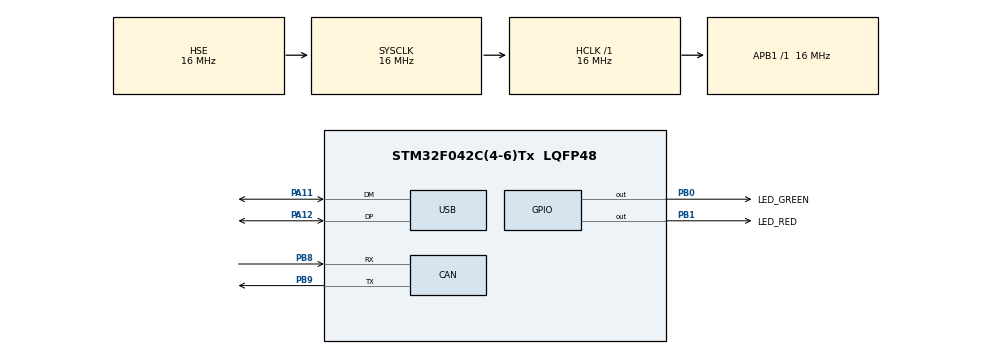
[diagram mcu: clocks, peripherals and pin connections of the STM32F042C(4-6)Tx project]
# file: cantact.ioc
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CAN.CalculateTimeBit=3000
CAN.CalculateTimeQuantum=1000.0
Mcu.Family=STM32F0
Mcu.Name=STM32F042C(4-6)Tx
Mcu.Package=LQFP48
NVIC.USB_IRQn=true\:0\:0\:false\:false\:true\:true\:true
PA11.Mode=Device
PA11.Signal=USB_DM
PA12.Mode=Device
PA12.Signal=USB_DP
PA13.Mode=Serial_Wire
PA13.Signal=SYS_SWDIO
PA14.Mode=Serial_Wire
PA14.Signal=SYS_SWCLK
PB0.GPIO_Label=LED_GREEN
PB0.Signal=GPIO_Output
PB1.GPIO_Label=LED_RED
PB1.Signal=GPIO_Output
PB8.Mode=Master
PB8.Signal=CAN_RX
PB9.Mode=Master
PB9.Signal=CAN_TX
PF0-OSC_IN.Mode=HSE-External-Oscillator
PF0-OSC_IN.Signal=RCC_OSC_IN
PF1-OSC_OUT.Mode=HSE-External-Oscillator
PF1-OSC_OUT.Signal=RCC_OSC_OUT
ProjectManager.HeapSize=0x200
ProjectManager.StackSize=0x400
ProjectManager.TargetToolchain=STM32CubeIDE
RCC.AHBFreq_Value=16000000
RCC.APB1Freq_Value=16000000
RCC.APB1TimFreq_Value=16000000
RCC.HCLKFreq_Value=16000000
RCC.HSE_VALUE=16000000
RCC.HSIState=RCC_HSI_ON
RCC.PLLMUL=RCC_PLL_MUL3
RCC.SYSCLKFreq_VALUE=16000000
RCC.SYSCLKSource=RCC_SYSCLKSOURCE_HSE
RCC.USBClockSelection=RCC_USBCLKSOURCE_PLL
RCC.USBFreq_Value=48000000
USB_DEVICE.CLASS_NAME_FS=CDC
USB_DEVICE.USBD_HandleTypeDef=hUsbDeviceFS
USB_DEVICE.VirtualMode=Cdc
USB_DEVICE.VirtualModeFS=Cdc_FS
VP_USB_DEVICE_VS_USB_DEVICE_CDC_FS.Mode=CDC_FS
board=cantact

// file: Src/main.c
/* USER CODE BEGIN Header */
/**
  ******************************************************************************
  * @file           : main.c
  * @brief          : Main program body
  ******************************************************************************
  * @attention
  *
  * <h2><center>&copy; Copyright (c) 2019 STMicroelectronics.
  * All rights reserved.</center></h2>
  *
  * This software component is licensed by ST under BSD 3-Clause license,
  * the "License"; You may not use this file except in compliance with the
  * License. You may obtain a copy of the License at:
  *                        opensource.org/licenses/BSD-3-Clause
  *
  ******************************************************************************
  */
/* USER CODE END Header */

#include "main.h"
#include "usb_device.h"

/* USER CODE BEGIN Includes */
#include "usbd_cdc_if.h"
#include "can.h"
#include "slcan.h"
#include "led.h"
/* USER CODE END Includes */

CAN_HandleTypeDef hcan;

void SystemClock_Config(void);
static void MX_GPIO_Init(void);
static void MX_CAN_Init(void);

int main(void)
{

  /* MCU Configuration--------------------------------------------------------*/

  /* Reset of all peripherals, Initializes the Flash interface and the Systick. */
  HAL_Init();

  /* Configure the system clock */
  SystemClock_Config();

  /* Initialize all configured peripherals */
  MX_GPIO_Init();
  MX_CAN_Init();
  MX_USB_DEVICE_Init();

  /* Infinite loop */
  while (1)
  {
	// turn on green LED
	HAL_GPIO_WritePin(LED_GREEN_GPIO_Port, LED_GREEN_Pin, GPIO_PIN_SET);

	// blink red LED for test
	HAL_GPIO_WritePin(LED_RED_GPIO_Port, LED_RED_Pin, GPIO_PIN_SET);
	HAL_Delay(100);
	HAL_GPIO_WritePin(LED_RED_GPIO_Port, LED_RED_Pin, GPIO_PIN_RESET);
	HAL_Delay(100);
	HAL_GPIO_WritePin(LED_RED_GPIO_Port, LED_RED_Pin, GPIO_PIN_SET);
	HAL_Delay(100);
	HAL_GPIO_WritePin(LED_RED_GPIO_Port, LED_RED_Pin, GPIO_PIN_RESET);

	// loop forever
	CAN_RxHeaderTypeDef rx_msg;
	uint8_t can_data_buf[8];
	uint32_t status;
	uint8_t msg_buf[SLCAN_MTU];

	for (;;) {
	  while (!is_can_msg_pending(CAN_RX_FIFO0))
		  led_process();
	  status = can_rx(&rx_msg, msg_buf, 3);
	  if (status == HAL_OK) {
		  status = slcan_parse_frame((uint8_t *)&msg_buf, &rx_msg, can_data_buf);
		  CDC_Transmit_FS(msg_buf, status);
	  }
	  led_process();
	}
  }
}

void SystemClock_Config(void)
{
  RCC_OscInitTypeDef RCC_OscInitStruct = {0};
  RCC_ClkInitTypeDef RCC_ClkInitStruct = {0};
  RCC_PeriphCLKInitTypeDef PeriphClkInit = {0};

  /** Initializes the CPU, AHB and APB busses clocks
  */
  RCC_OscInitStruct.OscillatorType = RCC_OSCILLATORTYPE_HSE;
  RCC_OscInitStruct.HSEState = RCC_HSE_ON;
  RCC_OscInitStruct.PLL.PLLState = RCC_PLL_ON;
  RCC_OscInitStruct.PLL.PLLSource = RCC_PLLSOURCE_HSE;
  RCC_OscInitStruct.PLL.PLLMUL = RCC_PLL_MUL3;
  RCC_OscInitStruct.PLL.PREDIV = RCC_PREDIV_DIV1;
  if (HAL_RCC_OscConfig(&RCC_OscInitStruct) != HAL_OK)
  {
    Error_Handler();
  }
  /** Initializes the CPU, AHB and APB busses clocks
  */
  RCC_ClkInitStruct.ClockType = RCC_CLOCKTYPE_HCLK|RCC_CLOCKTYPE_SYSCLK
                              |RCC_CLOCKTYPE_PCLK1;
  RCC_ClkInitStruct.SYSCLKSource = RCC_SYSCLKSOURCE_HSE;
  RCC_ClkInitStruct.AHBCLKDivider = RCC_SYSCLK_DIV1;
  RCC_ClkInitStruct.APB1CLKDivider = RCC_HCLK_DIV1;

  if (HAL_RCC_ClockConfig(&RCC_ClkInitStruct, FLASH_LATENCY_0) != HAL_OK)
  {
    Error_Handler();
  }
  PeriphClkInit.PeriphClockSelection = RCC_PERIPHCLK_USB;
  PeriphClkInit.UsbClockSelection = RCC_USBCLKSOURCE_PLL;

  if (HAL_RCCEx_PeriphCLKConfig(&PeriphClkInit) != HAL_OK)
  {
    Error_Handler();
  }
}

static void MX_CAN_Init(void)
{

  hcan.Instance = CAN;
  hcan.Init.Prescaler = 16;
  hcan.Init.Mode = CAN_MODE_NORMAL;
  hcan.Init.SyncJumpWidth = CAN_SJW_1TQ;
  hcan.Init.TimeSeg1 = CAN_BS1_1TQ;
  hcan.Init.TimeSeg2 = CAN_BS2_1TQ;
  hcan.Init.TimeTriggeredMode = DISABLE;
  hcan.Init.AutoBusOff = DISABLE;
  hcan.Init.AutoWakeUp = DISABLE;
  hcan.Init.AutoRetransmission = DISABLE;
  hcan.Init.ReceiveFifoLocked = DISABLE;
  hcan.Init.TransmitFifoPriority = DISABLE;
  if (HAL_CAN_Init(&hcan) != HAL_OK)
  {
    Error_Handler();
  }

}

static void MX_GPIO_Init(void)
{
  GPIO_InitTypeDef GPIO_InitStruct = {0};

  /* GPIO Ports Clock Enable */
  __HAL_RCC_GPIOF_CLK_ENABLE();
  __HAL_RCC_GPIOB_CLK_ENABLE();
  __HAL_RCC_GPIOA_CLK_ENABLE();

  /*Configure GPIO pin Output Level */
  HAL_GPIO_WritePin(GPIOB, LED_GREEN_Pin|LED_RED_Pin, GPIO_PIN_RESET);

  /*Configure GPIO pins : LED_GREEN_Pin LED_RED_Pin */
  GPIO_InitStruct.Pin = LED_GREEN_Pin|LED_RED_Pin;
  GPIO_InitStruct.Mode = GPIO_MODE_OUTPUT_PP;
  GPIO_InitStruct.Pull = GPIO_NOPULL;
  GPIO_InitStruct.Speed = GPIO_SPEED_FREQ_LOW;
  HAL_GPIO_Init(GPIOB, &GPIO_InitStruct);

}

void Error_Handler(void)
{
}

/************************ (C) COPYRIGHT STMicroelectronics *****END OF FILE****/
